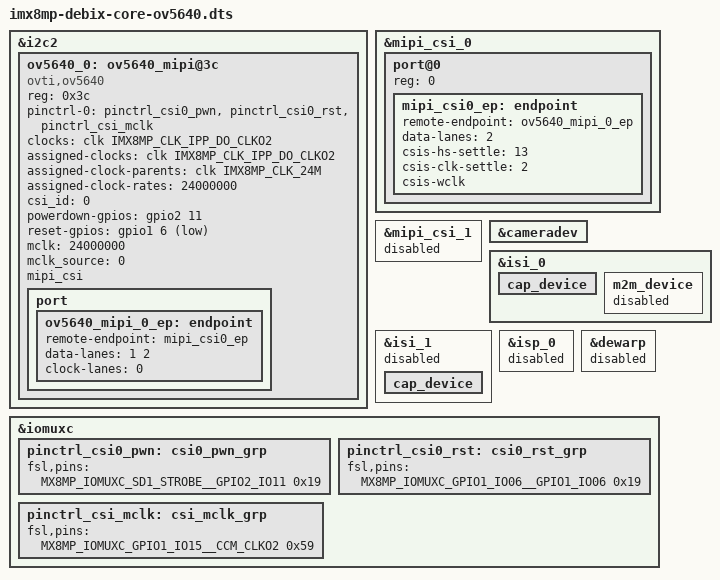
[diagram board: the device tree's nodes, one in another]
// SPDX-License-Identifier: GPL-2.0+
/*
 * Copyright 2020 NXP
 */

#include "imx8mp-debix-core-board.dts"

&i2c2 {
        ov5640_0: ov5640_mipi@3c {
                compatible = "ovti,ov5640";
                reg = <0x3c>;
                pinctrl-names = "default";
                pinctrl-0 = <&pinctrl_csi0_pwn>, <&pinctrl_csi0_rst>, <&pinctrl_csi_mclk>;
                clocks = <&clk IMX8MP_CLK_IPP_DO_CLKO2>;
                clock-names = "xclk";
                assigned-clocks = <&clk IMX8MP_CLK_IPP_DO_CLKO2>;
                assigned-clock-parents = <&clk IMX8MP_CLK_24M>;
                assigned-clock-rates = <24000000>;
                csi_id = <0>;
                powerdown-gpios = <&gpio2 11 GPIO_ACTIVE_HIGH>;
                reset-gpios = <&gpio1 6 GPIO_ACTIVE_LOW>;
                mclk = <24000000>;
                mclk_source = <0>;
                mipi_csi;
                status = "okay";
                port {
                        ov5640_mipi_0_ep: endpoint {
                                ///delete-property/ remote-endpoint;
                                remote-endpoint = <&mipi_csi0_ep>;
                                data-lanes = <1 2>;
                                clock-lanes = <0>;
                        };
                };
        };

};

&mipi_csi_0 {
        #address-cells = <1>;
        #size-cells = <0>;
        status = "okay";

        port@0 {
                reg = <0>;
                mipi_csi0_ep: endpoint {
                        ///delete-property/ remote-endpoint;
                        remote-endpoint = <&ov5640_mipi_0_ep>;
                        data-lanes = <2>;
                        csis-hs-settle = <13>;
                        csis-clk-settle = <2>;
                        csis-wclk;
                };
        };

};
&mipi_csi_1 {
        #address-cells = <1>;
        #size-cells = <0>;
        status = "disabled";
};
&cameradev {
        status = "okay";
};

&isi_0 {
        status = "okay";
        cap_device {
                status = "okay";
        };

        m2m_device {
                status = "disabled";
        };


};

&isi_1 {
        status = "disabled";
        cap_device {
                status = "okay";
        };


};

&isp_0 {
        status = "disabled";
};

&dewarp {
        status = "disabled";
};

&iomuxc {

pinctrl_csi0_pwn: csi0_pwn_grp {
                fsl,pins = <
                        MX8MP_IOMUXC_SD1_STROBE__GPIO2_IO11 0x19
                >;
        };

        pinctrl_csi0_rst: csi0_rst_grp {
                fsl,pins = <
                        MX8MP_IOMUXC_GPIO1_IO06__GPIO1_IO06             0x19
                >;
        };

        pinctrl_csi_mclk: csi_mclk_grp {
                fsl,pins = <
                        MX8MP_IOMUXC_GPIO1_IO15__CCM_CLKO2      0x59
                >;
        };
};
 
